# USB_USB2SS_SUPPRTCAP3_31000980h register map
Vendor: Texas Instruments
Peripheral module from a debugger description file (folder am62D).
Registers are 32-bit, read-only, reset 0x0 unless marked. A register's access mark holds for its fields unless they carry their own. Offsets are as the file gives them; lines under a group give offsets from that group; [hi:lo] are bit positions; {n}, {i} and the like mark numbered series; 'fields as' and 'values as' point back to an identical list; <NAME> marks a mode.

## USB2SS_SUPPRTCAP3
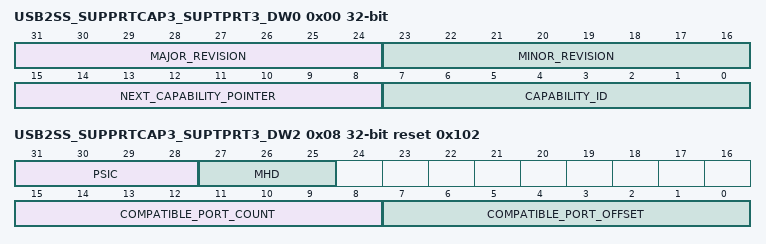
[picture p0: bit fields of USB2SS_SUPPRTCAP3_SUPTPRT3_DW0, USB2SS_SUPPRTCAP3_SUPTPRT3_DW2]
0x00 USB2SS_SUPPRTCAP3_SUPTPRT3_DW0 — Register SUPTPRT3_DW0
  [31:24] MAJOR_REVISION — MAJOR_REVISIONFor a description of this standard USB register field, see the eXtensible Host Controller Interface for Universal Serial Bus [USB] Specification 3.0. Reset Source: rst_mod_g_rst_n
  [23:16] MINOR_REVISION — MINOR_REVISIONFor a description of this standard USB register field, see the eXtensible Host Controller Interface for Universal Serial Bus [USB] Specification 3.0. Reset Source: rst_mod_g_rst_n
  [15:8] NEXT_CAPABILITY_POINTER — NEXT_CAPABILITY_POINTERFor a description of this standard USB register field, see the eXtensible Host Controller Interface for Universal Serial Bus [USB] Specification 3.0. Reset Source: rst_mod_g_rst_n
  [7:0] CAPABILITY_ID — CAPABILITY_IDFor a description of this standard USB register field, see the eXtensible Host Controller Interface for Universal Serial Bus [USB] Specification 3.0. Reset Source: rst_mod_g_rst_n
0x04 USB2SS_SUPPRTCAP3_SUPTPRT3_DW1 — Register SUPTPRT3_DW1
  [31:0] NAME_STRING — NAME_STRINGFor a description of this standard USB register field, see the eXtensible Host Controller Interface for Universal Serial Bus [USB] Specification 3.0. Reset Source: rst_mod_g_rst_n
0x08 USB2SS_SUPPRTCAP3_SUPTPRT3_DW2 reset 0x102 — SUPTPRT3_DW2For a description of this standard USB register field, see the eXtensible Host Controller Interface for Universal Serial Bus (USB) Specification 3.0.
  [31:28] PSIC — PSIC Reset Source: rst_mod_g_rst_n
  [27:25] MHD — Hub DepthFor a description of this standard USB register field, see the eXtensible Host Controller Interface for Universal Serial Bus [USB] Specification 3.0. Reset Source: rst_mod_g_rst_n
  [15:8] COMPATIBLE_PORT_COUNT — COMPATIBLE_PORT_COUNTFor a description of this standard USB register field, see the eXtensible Host Controller Interface for Universal Serial Bus [USB] Specification 3.0. Reset Source: rst_mod_g_rst_n
  [7:0] COMPATIBLE_PORT_OFFSET — COMPATIBLE_PORT_OFFSETFor a description of this standard USB register field, see the eXtensible Host Controller Interface for Universal Serial Bus [USB] Specification 3.0. Reset Source: rst_mod_g_rst_n
0x0C USB2SS_SUPPRTCAP3_SUPTPRT3_DW3 — SUPTPRT3_DW3
  [4:0] PROTCL_SLT_TY — Protocol Slot Type Reset Source: rst_mod_g_rst_n
